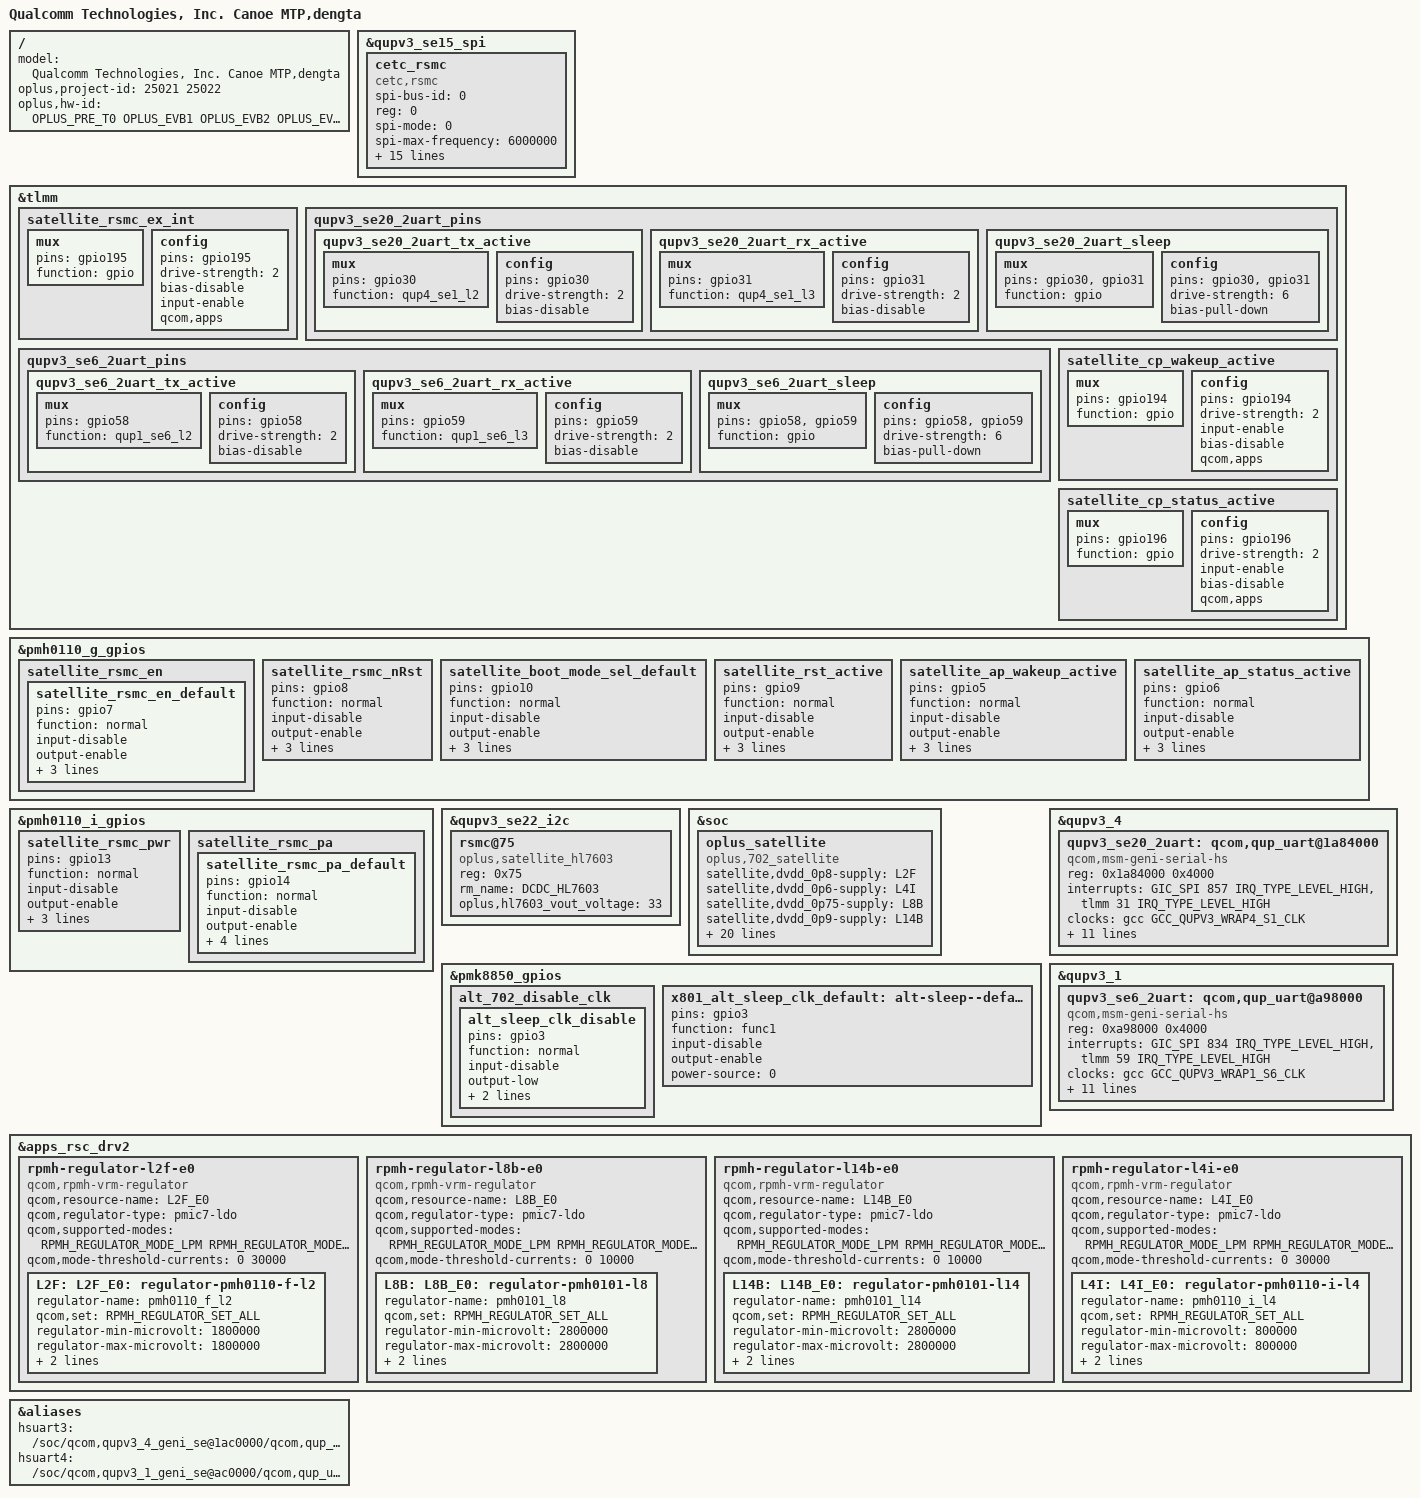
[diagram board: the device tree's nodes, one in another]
/dts-v1/;
/plugin/;
#include "../qcom/canoe-mtp-overlay.dtso"
#include <dt-bindings/oplus/hw-id.h>
#include "canoe_overlay_common.dtsi"
#include "dengta_overlay_common.dtsi"
#include "mm/dengta-25021-canoe-mm.dtsi"
#include "security/dengta-25021-canoe-security.dtsi"
#include "sensor/dengta-sensor-25021.dtsi"
#include "tp/dengta-oplus-tp-25021.dtsi"
#include "oplus_misc/oplus-misc-25021.dtsi"
#include "oplus_icc/dengta-25021-icc.dtsi"
#include "oplus_chg/oplus-chg-25021.dtsi"
#include "oplus_nfc/dengta-sn220.dtsi"
#include "oplus_uff/oplus-uff-25021.dtsi"
#include <dt-bindings/interrupt-controller/arm-gic.h>
#include <dt-bindings/interconnect/qcom,canoe.h>
#include <dt-bindings/interrupt-controller/irq.h>
#include <dt-bindings/spmi/spmi.h>

/ {
    model = "Qualcomm Technologies, Inc. Canoe MTP,dengta";
    oplus,project-id = <25021 25022>;
    oplus,hw-id = <OPLUS_PRE_T0 OPLUS_EVB1 OPLUS_EVB2 OPLUS_EVB3 OPLUS_T0 OPLUS_EVT1 OPLUS_EVT2 OPLUS_DVT1 OPLUS_DVT2 OPLUS_PVT1>;
};

//x801
&qupv3_se15_spi {
    status = "ok";
    #address-cells = <1>;
	#size-cells = <0>;

    cetc_rsmc {
        compatible = "cetc,rsmc";
        spi-bus-id = <0>;
        reg = <0>;
        spi-mode = <0>;
        spi-max-frequency = <6000000>;
        pa_gpio = <&pmh0110_i_gpios 14 GPIO_ACTIVE_LOW>;
        en_gpio = <&pmh0110_g_gpios 7 GPIO_ACTIVE_LOW>;
        pinctrl-names = "irq_active","default";
        pinctrl-0 = <&satellite_rsmc_ex_int>;
        pinctrl-1 = <&satellite_rsmc_en_default>;
        irq_gpio = <&tlmm 195 0x00>;
        mcu_rst_gpio = <&pmh0110_g_gpios 8 GPIO_ACTIVE_LOW>;

        rsmc-tcxo-vcc-type = <1>;
        tcxo_pwr_gpio = <&pmh0110_i_gpios 13 GPIO_ACTIVE_LOW>;
        tcxo_pwr_after_delay_ms = <10>;
        rsmc_enable_x801;
		platform = <1>;
        dvdd_2p8-supply = <&L8B>;
        bob2-supply = <&BOB2>;
   };
};

&tlmm {

    satellite_rsmc_ex_int:satellite_rsmc_ex_int {
        mux {
            pins = "gpio195";
            function = "gpio";
        };

        config {
            pins = "gpio195";
			drive-strength = <2>;
            bias-disable;
			input-enable;
            qcom,apps;
        };
    };
};

&pmh0110_g_gpios {
    satellite_rsmc_en {
        satellite_rsmc_en_default:satellite_rsmc_en_default {
            pins = "gpio7";
            function = "normal";
            input-disable;
            output-enable;
            output-high;
            power-source = <1>;
            qcom,drive-strength = <2>;
        };
    };
};



&pmh0110_g_gpios{
    satellite_rsmc_nRst:satellite_rsmc_nRst {
		pins = "gpio8";
		function = "normal";
        input-disable;
        output-enable;
        output-high;
        power-source = <1>;
        qcom,drive-strength = <2>;
	};
};

&pmh0110_i_gpios{
    satellite_rsmc_pwr:satellite_rsmc_pwr {
        pins = "gpio13";
		function = "normal";
        input-disable;
        output-enable;
        output-high;
        power-source = <0>;
        qcom,drive-strength = <2>;
    };
};


&pmh0110_i_gpios{
    satellite_rsmc_pa {
        satellite_rsmc_pa_default:satellite_rsmc_pa_default {
            pins = "gpio14";
            function = "normal";
            input-disable;
            output-enable;
            output-high;
            bias-disable;
            power-source = <0>;
            qcom,drive-strength = <2>;
        };
    };
};


&qupv3_se22_i2c {
     status = "ok";
     rsmc@75 {
         compatible = "oplus,satellite_hl7603";
         reg = <0x75>;
         rm_name = "DCDC_HL7603";
         oplus,hl7603_vout_voltage = <33>;
     };
 };

//dxs702

&soc{
    oplus_satellite{
        compatible = "oplus,702_satellite";
        satellite,dvdd_0p8-supply = <&L2F>;
        satellite,dvdd_0p6-supply = <&L4I>;
        satellite,dvdd_0p75-supply = <&L8B>;
        satellite,dvdd_0p9-supply = <&L14B>;

        pinctrl-names = "alt_sleep_clk_disable", "alt_sleep_clk_default", "default";
        pinctrl-0 = <&alt_sleep_clk_disable>;
        pinctrl-1 = <&x801_alt_sleep_clk_default>;
        pinctrl-2 = <&satellite_rst_active>,<&satellite_ap_wakeup_active>,<&satellite_ap_status_active>;

        oplus,oplus-satellite-boot-sel = <&pmh0110_g_gpios 10 GPIO_ACTIVE_LOW>;//boot sel
        oplus,oplus-satellite-rst= <&pmh0110_g_gpios 9 GPIO_ACTIVE_LOW>;//hostrstn_in

        oplus,oplus-satellite-ap-wakeup-cp = <&pmh0110_g_gpios 5 GPIO_ACTIVE_LOW>;//ap wake up bb
        oplus,oplus-satellite-cp-wakeup-ap = <&tlmm 194 GPIO_ACTIVE_LOW>;//bb wake up ap
        oplus,oplus-satellite-ap-status = <&pmh0110_g_gpios 6 GPIO_ACTIVE_LOW>;
        oplus,oplus-satellite-cp-status = <&tlmm 196 GPIO_ACTIVE_LOW>;

        oplus,oplus-satellite-pa = <&pmh0110_i_gpios 14 GPIO_ACTIVE_LOW>;
        bob2-supply = <&BOB2>;
    };
};


#include <dt-bindings/regulator/qcom,rpmh-regulator.h>


&pmk8850_gpios {
	alt_702_disable_clk {
		alt_sleep_clk_disable: alt_sleep_clk_disable {
			pins = "gpio3";
			function = "normal";
			input-disable;
			output-low;
			bias-disable;
			power-source = <0>;
		};
	};
};


&pmk8850_gpios{
    x801_alt_sleep_clk_default: alt-sleep--default-state {
 		pins = "gpio3";
 		function = "func1";
 		input-disable;
 		output-enable;
 		power-source = <0>; 
 	};
};

&pmh0110_g_gpios{
    satellite_boot_mode_sel_default: satellite_boot_mode_sel_default {
        pins = "gpio10";
        function = "normal";
        input-disable;
        output-enable;
        output-high;
        power-source = <1>;
        qcom,drive-strength = <2>;
  };
};

&pmh0110_g_gpios{
    satellite_rst_active: satellite_rst_active {
        pins = "gpio9";
        function = "normal";
        input-disable;
        output-enable;
        output-low;
        power-source = <1>;
        qcom,drive-strength = <2>;
  };
};


&tlmm {
  	qupv3_se20_2uart_pins: qupv3_se20_2uart_pins {
		qupv3_se20_2uart_tx_active: qupv3_se20_2uart_tx_active {
			mux {
				pins = "gpio30";
				function = "qup4_se1_l2";
			};

			config {
				pins = "gpio30";
				drive-strength = <2>;
				bias-disable;
			};
		};

		qupv3_se20_2uart_rx_active: qupv3_se20_2uart_rx_active {
			mux {
				pins = "gpio31";
				function = "qup4_se1_l3";
			};

			config {
				pins = "gpio31";
				drive-strength = <2>;
				bias-disable;
			};
		};

		qupv3_se20_2uart_sleep: qupv3_se20_2uart_sleep {
 			mux {
 				pins = "gpio30", "gpio31";
 				function = "gpio";
 			};

 			config {
 				pins = "gpio30", "gpio31";
 				drive-strength = <6>;
 				bias-pull-down;
 			};
 		};



	};

};


&tlmm {
  	qupv3_se6_2uart_pins: qupv3_se6_2uart_pins {
		qupv3_se6_2uart_tx_active: qupv3_se6_2uart_tx_active {
			mux {
				pins = "gpio58";
				function = "qup1_se6_l2";
			};

			config {
				pins = "gpio58";
				drive-strength = <2>;
				bias-disable;
			};
		};

		qupv3_se6_2uart_rx_active: qupv3_se6_2uart_rx_active {
			mux {
				pins = "gpio59";
				function = "qup1_se6_l3";
			};

			config {
				pins = "gpio59";
				drive-strength = <2>;
				bias-disable;
			};
		};

		qupv3_se6_2uart_sleep: qupv3_se6_2uart_sleep {
 			mux {
 				pins = "gpio58", "gpio59";
 				function = "gpio";
 			};

 			config {
 				pins = "gpio58", "gpio59";
 				drive-strength = <6>;
 				bias-pull-down;
 			};
 		};



	};

};

&pmh0110_g_gpios {
      //#ifdef OPLUS_FEATURE_702_satellite
  satellite_ap_wakeup_active: satellite_ap_wakeup_active {
        pins = "gpio5";
        function = "normal";
        input-disable;
        output-enable;
        output-low;
        power-source = <1>;
        qcom,drive-strength = <2>;
  };
  //#endif
};

&pmh0110_g_gpios {
      //#ifdef OPLUS_FEATURE_702_satellite
  satellite_ap_status_active: satellite_ap_status_active {
        pins = "gpio6";
        function = "normal";
        input-disable;
        output-enable;
        output-low;
        power-source = <1>;
        qcom,drive-strength = <2>;
  };
  //#endif
};

&tlmm {
  //#ifdef OPLUS_FEATURE_702_satellite
  satellite_cp_wakeup_active: satellite_cp_wakeup_active {
    mux {
      pins = "gpio194";
      function = "gpio";
    };
    config {
      pins = "gpio194";
      drive-strength = <2>;
      input-enable;
      bias-disable;
      qcom,apps;
    };
  };
  //#endif
};

&tlmm {
  //#ifdef OPLUS_FEATURE_702_satellite
  satellite_cp_status_active: satellite_cp_status_active {
    mux {
      pins = "gpio196";
      function = "gpio";
    };
    config {
      pins = "gpio196";
      drive-strength = <2>;
      input-enable;
      bias-disable;
      qcom,apps;
    };
  };
  //#endif
};

&qupv3_4{
    qupv3_se20_2uart: qcom,qup_uart@1a84000 {
 		compatible = "qcom,msm-geni-serial-hs";
 		reg = <0x1a84000 0x4000>;
 		reg-names = "se_phys";
 		interrupts = <GIC_SPI 857 IRQ_TYPE_LEVEL_HIGH>, <&tlmm 31 IRQ_TYPE_LEVEL_HIGH>;
        clock-names = "se-clk";
        clocks = <&gcc GCC_QUPV3_WRAP4_S1_CLK>;
 		interconnect-names = "qup-core", "qup-config", "qup-memory";
 		interconnects =
        <&clk_virt MASTER_QUP_CORE_4 &clk_virt SLAVE_QUP_CORE_4>,
        <&gem_noc MASTER_APPSS_PROC &config_noc SLAVE_QUP_4>,
        <&aggre2_noc MASTER_QUP_4 &mc_virt  SLAVE_EBI1>;
 		pinctrl-names = "active", "sleep","shutdown","default";
 		pinctrl-0 = <&qupv3_se20_2uart_tx_active>, <&qupv3_se20_2uart_rx_active>;
 		pinctrl-1 = <&qupv3_se20_2uart_sleep>;
        pinctrl-2 = <&qupv3_se20_2uart_sleep>;
        pinctrl-3 = <&qupv3_se20_2uart_sleep>;
 		qcom,wakeup-byte = <0xFD>;
		status = "ok";
 	};
};

&qupv3_1{
    qupv3_se6_2uart: qcom,qup_uart@a98000 {
 		compatible = "qcom,msm-geni-serial-hs";
 		reg = <0xa98000 0x4000>;
 		reg-names = "se_phys";
 		interrupts = <GIC_SPI 834 IRQ_TYPE_LEVEL_HIGH>, <&tlmm 59 IRQ_TYPE_LEVEL_HIGH>;
        clock-names = "se-clk";
        clocks = <&gcc GCC_QUPV3_WRAP1_S6_CLK>;
 		interconnect-names = "qup-core", "qup-config", "qup-memory";
 		interconnects =
        <&clk_virt MASTER_QUP_CORE_1 &clk_virt SLAVE_QUP_CORE_1>,
        <&gem_noc MASTER_APPSS_PROC &config_noc SLAVE_QUP_1>,
        <&aggre1_noc MASTER_QUP_1 &mc_virt  SLAVE_EBI1>;
 		pinctrl-names = "active", "sleep","shutdown","default";
 		pinctrl-0 = <&qupv3_se6_2uart_tx_active>, <&qupv3_se6_2uart_rx_active>;
 		pinctrl-1 = <&qupv3_se6_2uart_sleep>;
        pinctrl-2 = <&qupv3_se6_2uart_sleep>;
        pinctrl-3 = <&qupv3_se6_2uart_sleep>;
 		qcom,wakeup-byte = <0xFD>;
		status = "ok";
 	};
};


#include <dt-bindings/regulator/qcom,rpmh-regulator-levels.h>
&apps_rsc_drv2 {
    rpmh-regulator-l2f-e0 {
		compatible = "qcom,rpmh-vrm-regulator";
		qcom,resource-name = "L2F_E0";
		qcom,regulator-type = "pmic7-ldo";
		qcom,supported-modes = <RPMH_REGULATOR_MODE_LPM
					RPMH_REGULATOR_MODE_AUTO>;
		qcom,mode-threshold-currents = <0 30000>;

        L2F: L2F_E0: pmh0110_f_l2: regulator-pmh0110-f-l2 {
			regulator-name = "pmh0110_f_l2";
			qcom,set = <RPMH_REGULATOR_SET_ALL>;
			regulator-min-microvolt = <1800000>;
			regulator-max-microvolt = <1800000>;
			qcom,init-voltage = <1800000>;
			qcom,init-mode = <RPMH_REGULATOR_MODE_AUTO>;
		};
	};

    rpmh-regulator-l8b-e0 {
 		compatible = "qcom,rpmh-vrm-regulator";
 		qcom,resource-name = "L8B_E0";
 		qcom,regulator-type = "pmic7-ldo";
 		qcom,supported-modes = <RPMH_REGULATOR_MODE_LPM
 					RPMH_REGULATOR_MODE_AUTO>;
 		qcom,mode-threshold-currents = <0 10000>;
 
 		L8B: L8B_E0: pmh0101_l8: regulator-pmh0101-l8 {
 			regulator-name = "pmh0101_l8";
 			qcom,set = <RPMH_REGULATOR_SET_ALL>;
 			regulator-min-microvolt = <2800000>;
 			regulator-max-microvolt = <2800000>;
 			qcom,init-voltage = <2800000>;
 			qcom,init-mode = <RPMH_REGULATOR_MODE_AUTO>;
 		};
 	};
 	rpmh-regulator-l14b-e0 {
 		compatible = "qcom,rpmh-vrm-regulator";
 		qcom,resource-name = "L14B_E0";
 		qcom,regulator-type = "pmic7-ldo";
 		qcom,supported-modes = <RPMH_REGULATOR_MODE_LPM
 					RPMH_REGULATOR_MODE_AUTO>;
 		qcom,mode-threshold-currents = <0 10000>;
 
 		L14B: L14B_E0: pmh0101_l14: regulator-pmh0101-l14 {
 			regulator-name = "pmh0101_l14";
 			qcom,set = <RPMH_REGULATOR_SET_ALL>;
 			regulator-min-microvolt = <2800000>;
 			regulator-max-microvolt = <2800000>;
 			qcom,init-voltage = <2800000>;
 			qcom,init-mode = <RPMH_REGULATOR_MODE_AUTO>;
 		};
 	};
    rpmh-regulator-l4i-e0 {
 		compatible = "qcom,rpmh-vrm-regulator";
 		qcom,resource-name = "L4I_E0";
 		qcom,regulator-type = "pmic7-ldo";
 		qcom,supported-modes = <RPMH_REGULATOR_MODE_LPM
 					RPMH_REGULATOR_MODE_AUTO>;
 		qcom,mode-threshold-currents = <0 30000>;
 
 		L4I: L4I_E0: pmh0110_i_l4: regulator-pmh0110-i-l4 {
 			regulator-name = "pmh0110_i_l4";
 			qcom,set = <RPMH_REGULATOR_SET_ALL>;
 			regulator-min-microvolt = <800000>;
 			regulator-max-microvolt = <800000>;
 			qcom,init-voltage = <800000>;
 			qcom,init-mode = <RPMH_REGULATOR_MODE_AUTO>;
 		};
 	};

};

&aliases{
    hsuart3	= "/soc/qcom,qupv3_4_geni_se@1ac0000/qcom,qup_uart@1a84000";
    hsuart4	= "/soc/qcom,qupv3_1_geni_se@ac0000/qcom,qup_uart@a98000";
};
